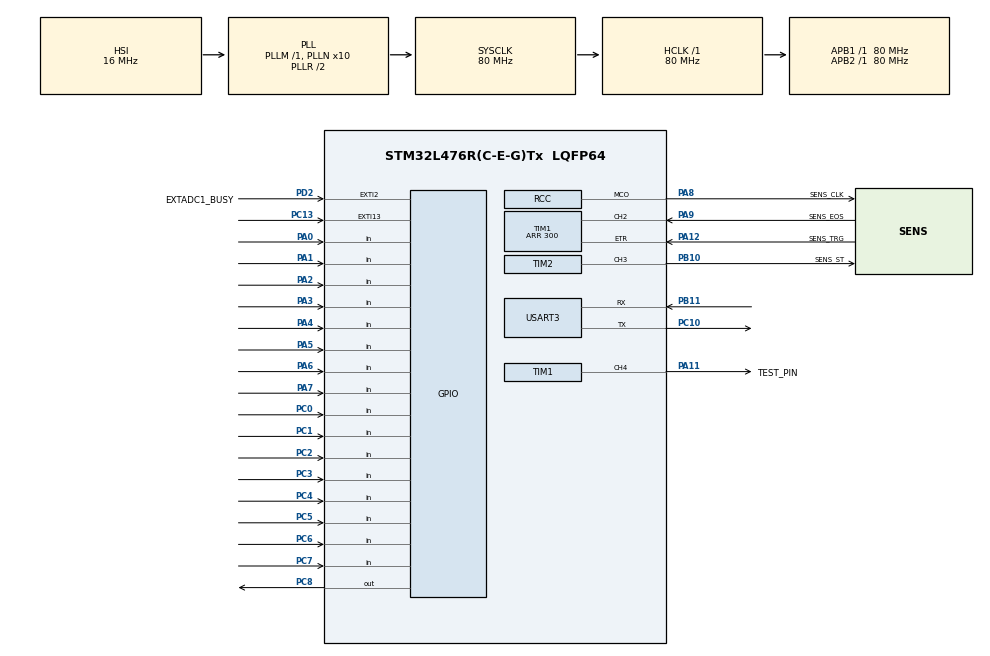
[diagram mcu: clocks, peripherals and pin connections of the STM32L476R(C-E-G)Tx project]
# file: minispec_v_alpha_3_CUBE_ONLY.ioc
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Dma.MEMTOMEM.0.Direction=DMA_MEMORY_TO_MEMORY
Dma.MEMTOMEM.0.Instance=DMA1_Channel1
Dma.MEMTOMEM.0.MemDataAlignment=DMA_MDATAALIGN_HALFWORD
Dma.MEMTOMEM.0.MemInc=DMA_MINC_ENABLE
Dma.MEMTOMEM.0.Mode=DMA_NORMAL
Dma.MEMTOMEM.0.PeriphDataAlignment=DMA_PDATAALIGN_HALFWORD
Dma.MEMTOMEM.0.PeriphInc=DMA_PINC_ENABLE
Dma.MEMTOMEM.0.Priority=DMA_PRIORITY_VERY_HIGH
Dma.MEMTOMEM.1.Direction=DMA_MEMORY_TO_MEMORY
Dma.MEMTOMEM.1.Instance=DMA2_Channel1
Dma.MEMTOMEM.1.MemDataAlignment=DMA_MDATAALIGN_HALFWORD
Dma.MEMTOMEM.1.MemInc=DMA_MINC_ENABLE
Dma.MEMTOMEM.1.Mode=DMA_NORMAL
Dma.MEMTOMEM.1.PeriphDataAlignment=DMA_PDATAALIGN_HALFWORD
Dma.MEMTOMEM.1.PeriphInc=DMA_PINC_ENABLE
Dma.MEMTOMEM.1.Priority=DMA_PRIORITY_VERY_HIGH
Dma.Request0=MEMTOMEM
Dma.Request1=MEMTOMEM
Mcu.Family=STM32L4
Mcu.Name=STM32L476R(C-E-G)Tx
Mcu.Package=LQFP64
NVIC.EXTI2_IRQn=true\:0\:0\:false\:true\:true\:1
NVIC.PriorityGroup=NVIC_PRIORITYGROUP_4
NVIC.TIM1_CC_IRQn=true\:0\:0\:false\:true\:true\:4
NVIC.TIM1_UP_TIM16_IRQn=true\:0\:0\:false\:true\:true\:3
NVIC.USART3_IRQn=true\:0\:0\:false\:true\:true\:2
PA0.Signal=GPIO_Input
PA1.Signal=GPIO_Input
PA11.GPIO_Label=TEST_PIN
PA11.GPIO_ModeDefaultPP=GPIO_MODE_AF_PP
PA11.GPIO_PuPd=GPIO_NOPULL
PA11.GPIO_Speed=GPIO_SPEED_FREQ_LOW
PA11.Signal=S_TIM1_CH4
PA12.GPIO_Label=SENS_TRG
PA12.GPIO_Mode=GPIO_MODE_AF_PP
PA12.GPIO_PuPd=GPIO_NOPULL
PA12.GPIO_Speed=GPIO_SPEED_FREQ_LOW
PA12.Signal=S_TIM1_ETR
PA13.Signal=SYS_JTMS-SWDIO
PA14.Signal=SYS_JTCK-SWCLK
PA2.Signal=GPIO_Input
PA3.Signal=GPIO_Input
PA4.Signal=GPIO_Input
PA5.Signal=GPIO_Input
PA6.Signal=GPIO_Input
PA7.Signal=GPIO_Input
PA8.GPIO_Label=SENS_CLK
PA8.GPIO_Mode=GPIO_MODE_AF_PP
PA8.GPIO_PuPd=GPIO_NOPULL
PA8.GPIO_Speed=GPIO_SPEED_FREQ_LOW
PA8.Mode=Clock-out
PA8.Signal=RCC_MCO
PA9.GPIO_Label=SENS_EOS
PA9.GPIO_ModeDefaultPP=GPIO_MODE_AF_PP
PA9.GPIO_PuPd=GPIO_NOPULL
PA9.GPIO_Speed=GPIO_SPEED_FREQ_LOW
PA9.Signal=S_TIM1_CH2
PB10.GPIO_Label=SENS_ST
PB10.GPIO_ModeDefaultPP=GPIO_MODE_AF_PP
PB10.GPIO_PuPd=GPIO_NOPULL
PB10.GPIO_Speed=GPIO_SPEED_FREQ_LOW
PB10.Signal=S_TIM2_CH3
PB11.Mode=Asynchronous
PB11.Signal=USART3_RX
PB3.Signal=SYS_JTDO-SWO
PC0.Signal=GPIO_Input
PC1.Signal=GPIO_Input
PC10.Mode=Asynchronous
PC10.Signal=USART3_TX
PC13.GPIO_ModeDefaultEXTI=GPIO_MODE_IT_RISING
PC13.GPIO_PuPd=GPIO_NOPULL
PC13.Signal=GPXTI13
PC14/OSC32_IN.Mode=LSE-External-Oscillator
PC14/OSC32_IN.Signal=RCC_OSC32_IN
PC15/OSC32_OUT.Mode=LSE-External-Oscillator
PC15/OSC32_OUT.Signal=RCC_OSC32_OUT
PC2.Signal=GPIO_Input
PC3.Signal=GPIO_Input
PC4.Signal=GPIO_Input
PC5.Signal=GPIO_Input
PC6.Signal=GPIO_Input
PC7.Signal=GPIO_Input
PC8.GPIO_ModeDefaultOutputPP=GPIO_MODE_OUTPUT_PP
PC8.GPIO_PuPd=GPIO_NOPULL
PC8.GPIO_Speed=GPIO_SPEED_FREQ_LOW
PC8.PinState=GPIO_PIN_RESET
PC8.Signal=GPIO_Output
PD2.GPIO_Label=EXTADC1_BUSY
PD2.GPIO_ModeDefaultEXTI=GPIO_MODE_IT_RISING
PD2.GPIO_PuPd=GPIO_NOPULL
PD2.Signal=GPXTI2
PH0/OSC_IN.Signal=RCC_OSC_IN
PH1/OSC_OUT.Signal=RCC_OSC_OUT
ProjectManager.HeapSize=0x2000
ProjectManager.StackSize=0x4000
ProjectManager.TargetToolchain=SW4STM32
RCC.ADCFreq_Value=64000000
RCC.AHBFreq_Value=80000000
RCC.APB1Freq_Value=80000000
RCC.APB1TimFreq_Value=80000000
RCC.APB2Freq_Value=80000000
RCC.APB2TimFreq_Value=80000000
RCC.CortexFreq_Value=80000000
RCC.HCLKFreq_Value=80000000
RCC.HSE_VALUE=8000000
RCC.HSI_VALUE=16000000
RCC.MSI_VALUE=4000000
RCC.PLLN=10
RCC.PLLSourceVirtual=RCC_PLLSOURCE_HSI
RCC.PREFETCH_ENABLE=1
RCC.RCC_MCO1Source=RCC_MCO1SOURCE_HSI
RCC.RCC_MCODiv=RCC_MCODIV_16
RCC.SYSCLKFreq_VALUE=80000000
RCC.SYSCLKSource=RCC_SYSCLKSOURCE_PLLCLK
RCC.USBFreq_Value=64000000
RCC.VCOOutputFreq_Value=160000000
RCC.VDD_VALUE=3.3
SH.S_TIM1_CH2.0=TIM1_CH2,Input_Capture2_from_TI2
SH.S_TIM1_CH4.0=TIM1_CH4,PWM Generation4 CH4
SH.S_TIM1_ETR.0=TIM1_ETR,ClockSourceETR_Mode2
SH.S_TIM2_CH3.0=TIM2_CH3,PWM Generation3 CH3
TIM1.Channel-Input_Capture2_from_TI2=TIM_CHANNEL_2
TIM1.Channel-PWM\ Generation4\ CH4=TIM_CHANNEL_4
TIM1.ClockPolarity=TIM_CLOCKPOLARITY_INVERTED
TIM1.OCMode_PWM-PWM\ Generation4\ CH4=TIM_OCMODE_PWM2
TIM1.OCPolarity_4=TIM_OCPOLARITY_HIGH
TIM1.Period=300
TIM1.Pulse-PWM\ Generation4\ CH4=80
TIM2.Channel-PWM\ Generation3\ CH3=TIM_CHANNEL_3
TIM2.OCMode_PWM-PWM\ Generation3\ CH3=TIM_OCMODE_PWM2
TIM2.OCPolarity_3=TIM_OCPOLARITY_HIGH
TIM2.Period=1100
TIM2.Prescaler=80
TIM2.Pulse-PWM\ Generation3\ CH3=1
TIM2.TIM_MasterOutputTrigger=TIM_TRGO_UPDATE
TIM2.TIM_MasterSlaveMode=TIM_MASTERSLAVEMODE_ENABLE
USART3.DMADisableonRxErrorParam=UART_ADVFEATURE_DMA_DISABLEONRXERROR
USART3.OverrunDisableParam=UART_ADVFEATURE_OVERRUN_DISABLE
USART3.VirtualMode-Asynchronous=VM_ASYNC
USART3.WordLength=WORDLENGTH_8B
VP_TIM1_VS_ClockSourceITR.Mode=TriggerSource_ITR1
VP_TIM1_VS_ControllerModeTrigger.Mode=Trigger Mode
VP_TIM1_VS_OPM.Mode=OPM_bit
VP_TIM2_VS_ClockSourceINT.Mode=Internal
VP_TIM2_VS_OPM.Mode=OPM_bit
VP_TIM5_VS_ClockSourceINT.Mode=Internal
board=NUCLEO-L476RG

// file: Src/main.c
/**
  ******************************************************************************
  * File Name          : main.c
  * Description        : Main program body
  ******************************************************************************
  *
  * COPYRIGHT(c) 2017 STMicroelectronics
  *
  * Redistribution and use in source and binary forms, with or without modification,
  * are permitted provided that the following conditions are met:
  *   1. Redistributions of source code must retain the above copyright notice,
  *      this list of conditions and the following disclaimer.
  *   2. Redistributions in binary form must reproduce the above copyright notice,
  *      this list of conditions and the following disclaimer in the documentation
  *      and/or other materials provided with the distribution.
  *   3. Neither the name of STMicroelectronics nor the names of its contributors
  *      may be used to endorse or promote products derived from this software
  *      without specific prior written permission.
  *
  * THIS SOFTWARE IS PROVIDED BY THE COPYRIGHT HOLDERS AND CONTRIBUTORS "AS IS"
  * AND ANY EXPRESS OR IMPLIED WARRANTIES, INCLUDING, BUT NOT LIMITED TO, THE
  * IMPLIED WARRANTIES OF MERCHANTABILITY AND FITNESS FOR A PARTICULAR PURPOSE ARE
  * DISCLAIMED. IN NO EVENT SHALL THE COPYRIGHT HOLDER OR CONTRIBUTORS BE LIABLE
  * FOR ANY DIRECT, INDIRECT, INCIDENTAL, SPECIAL, EXEMPLARY, OR CONSEQUENTIAL
  * DAMAGES (INCLUDING, BUT NOT LIMITED TO, PROCUREMENT OF SUBSTITUTE GOODS OR
  * SERVICES; LOSS OF USE, DATA, OR PROFITS; OR BUSINESS INTERRUPTION) HOWEVER
  * CAUSED AND ON ANY THEORY OF LIABILITY, WHETHER IN CONTRACT, STRICT LIABILITY,
  * OR TORT (INCLUDING NEGLIGENCE OR OTHERWISE) ARISING IN ANY WAY OUT OF THE USE
  * OF THIS SOFTWARE, EVEN IF ADVISED OF THE POSSIBILITY OF SUCH DAMAGE.
  *
  ******************************************************************************
  */
#include "main.h"
#include "stm32l4xx_hal.h"
#include "dma.h"
#include "tim.h"
#include "usart.h"
#include "gpio.h"

/* USER CODE BEGIN Includes */
#include "stdio.h"
#include "string.h"
/* USER CODE END Includes */

/* USER CODE BEGIN PV */
/* Private variables ---------------------------------------------------------*/

/* USER CODE END PV */

void SystemClock_Config(void);
void Error_Handler(void);
static void MX_NVIC_Init(void);

/* USER CODE BEGIN PFP */
/* Private function prototypes -----------------------------------------------*/

/* USER CODE END PFP */

/* USER CODE BEGIN 0 */
volatile uint8_t cmd_flag;
volatile uint16_t cmd_bytes;
/* USER CODE END 0 */

int main(void)
{

  /* MCU Configuration----------------------------------------------------------*/

  /* Reset of all peripherals, Initializes the Flash interface and the Systick. */
  HAL_Init();

  /* Configure the system clock */
  SystemClock_Config();

  /* Initialize all configured peripherals */
  MX_GPIO_Init();
  MX_DMA_Init();
  MX_TIM2_Init();
  MX_TIM1_Init();
  MX_TIM5_Init();
  MX_USART3_UART_Init();

  /* Initialize interrupts */
  MX_NVIC_Init();

  /* USER CODE BEGIN 2 */

	//timer

	// ST
	TIM2->CCER |= TIM_CCER_CC3E;

	// TEST
	TIM1->CCER |= TIM_CCER_CC4E;
	__HAL_TIM_MOE_ENABLE( &htim1 );

	//start tim2 (ST)
	__HAL_TIM_ENABLE( &htim2 );

//	//modbus activation
//	uint32_t cr1 = 0;
//	char c;
//	//save cr1 status + reset RE and UE bit for modifying ADD[7:0]
//	cr1 = USART3->CR1;
//	USART3->CR1 &= ~(USART_CR1_RE | USART_CR1_UE);
//
//	c = '\r';
//	USART3->CR2 = (USART_CR2_ADD_Msk & (c << USART_CR2_ADD_Pos));
//
//	// restore RE and UE bit
//	USART3->CR1 = cr1;
//	//enable char match IR
//	USART3->CR1 |= USART_CR1_CMIE;
//
//	static uint8_t recv_buf[51];
//	memset( recv_buf, 0, 50 );
//	recv_buf[50] = '\0';
//
//	static uint8_t send_buf[51];
//	memset( send_buf, 'a', 50 );
//	send_buf[50] = '\0';
//	HAL_UART_Receive_IT( &huart3, recv_buf, 50 );
  /* USER CODE END 2 */

  /* Infinite loop */
	while( 1 )
	{

  /* USER CODE BEGIN 3 */

		/* TIMER TEST */
//		TIM_CCxChannelCmd((&htim2)->Instance, TIM_CHANNEL_3, TIM_CCx_ENABLE);
//		HAL_TIM_OC_Start(&htim1, TIM_CHANNEL_2); // HACK as PWM_START do not start
// TIM2 CH3 high @ first rising edge (first full pulse) -->> pulse 1
// low @ 10th rising edge (9 full pulses before) -->> period 9
// with low also update event (ARR overflow)
//		HAL_Delay( 50 );
		/* UART TEST*/

//		if( cmd_flag != 0 )
//		{
//			cmd_flag = 0;
//
//			if( memchr( (const void *) recv_buf, 'S', cmd_bytes ) != NULL )
//			{
//
////				HAL_UART_Transmit( &huart3, (uint8_t *) "\n", 1, 100 );
//				HAL_UART_Transmit( &huart3, (uint8_t *) send_buf, sizeof(send_buf), 8000000 );
////				HAL_UART_Transmit( &huart3, (uint8_t *) "\n", 1, 100 );
//				HAL_Delay( 50 );
//			}
//			memset( recv_buf, 0, cmd_bytes );
//			cmd_bytes = 0;
//			HAL_UART_Receive_IT( &huart3, recv_buf, 50 );
//		}
	}
  /* USER CODE END 3 */

}

/** System Clock Configuration
*/
void SystemClock_Config(void)
{

  RCC_OscInitTypeDef RCC_OscInitStruct;
  RCC_ClkInitTypeDef RCC_ClkInitStruct;
  RCC_PeriphCLKInitTypeDef PeriphClkInit;

    /**Initializes the CPU, AHB and APB busses clocks
    */
  RCC_OscInitStruct.OscillatorType = RCC_OSCILLATORTYPE_HSI;
  RCC_OscInitStruct.HSIState = RCC_HSI_ON;
  RCC_OscInitStruct.HSICalibrationValue = 16;
  RCC_OscInitStruct.PLL.PLLState = RCC_PLL_ON;
  RCC_OscInitStruct.PLL.PLLSource = RCC_PLLSOURCE_HSI;
  RCC_OscInitStruct.PLL.PLLM = 1;
  RCC_OscInitStruct.PLL.PLLN = 10;
  RCC_OscInitStruct.PLL.PLLP = RCC_PLLP_DIV7;
  RCC_OscInitStruct.PLL.PLLQ = RCC_PLLQ_DIV2;
  RCC_OscInitStruct.PLL.PLLR = RCC_PLLR_DIV2;
  if (HAL_RCC_OscConfig(&RCC_OscInitStruct) != HAL_OK)
  {
    Error_Handler();
  }

    /**Initializes the CPU, AHB and APB busses clocks
    */
  RCC_ClkInitStruct.ClockType = RCC_CLOCKTYPE_HCLK|RCC_CLOCKTYPE_SYSCLK
                              |RCC_CLOCKTYPE_PCLK1|RCC_CLOCKTYPE_PCLK2;
  RCC_ClkInitStruct.SYSCLKSource = RCC_SYSCLKSOURCE_PLLCLK;
  RCC_ClkInitStruct.AHBCLKDivider = RCC_SYSCLK_DIV1;
  RCC_ClkInitStruct.APB1CLKDivider = RCC_HCLK_DIV1;
  RCC_ClkInitStruct.APB2CLKDivider = RCC_HCLK_DIV1;

  if (HAL_RCC_ClockConfig(&RCC_ClkInitStruct, FLASH_LATENCY_4) != HAL_OK)
  {
    Error_Handler();
  }

  PeriphClkInit.PeriphClockSelection = RCC_PERIPHCLK_USART3;
  PeriphClkInit.Usart3ClockSelection = RCC_USART3CLKSOURCE_PCLK1;
  if (HAL_RCCEx_PeriphCLKConfig(&PeriphClkInit) != HAL_OK)
  {
    Error_Handler();
  }

  HAL_RCC_MCOConfig(RCC_MCO1, RCC_MCO1SOURCE_HSI, RCC_MCODIV_16);

    /**Configure the main internal regulator output voltage
    */
  if (HAL_PWREx_ControlVoltageScaling(PWR_REGULATOR_VOLTAGE_SCALE1) != HAL_OK)
  {
    Error_Handler();
  }

    /**Configure the Systick interrupt time
    */
  HAL_SYSTICK_Config(HAL_RCC_GetHCLKFreq()/1000);

    /**Configure the Systick
    */
  HAL_SYSTICK_CLKSourceConfig(SYSTICK_CLKSOURCE_HCLK);

  /* SysTick_IRQn interrupt configuration */
  HAL_NVIC_SetPriority(SysTick_IRQn, 0, 0);
}

/** NVIC Configuration
*/
static void MX_NVIC_Init(void)
{
  /* EXTI2_IRQn interrupt configuration */
  HAL_NVIC_SetPriority(EXTI2_IRQn, 0, 0);
  HAL_NVIC_EnableIRQ(EXTI2_IRQn);
  /* USART3_IRQn interrupt configuration */
  HAL_NVIC_SetPriority(USART3_IRQn, 0, 0);
  HAL_NVIC_EnableIRQ(USART3_IRQn);
  /* TIM1_UP_TIM16_IRQn interrupt configuration */
  HAL_NVIC_SetPriority(TIM1_UP_TIM16_IRQn, 0, 0);
  HAL_NVIC_EnableIRQ(TIM1_UP_TIM16_IRQn);
  /* TIM1_CC_IRQn interrupt configuration */
  HAL_NVIC_SetPriority(TIM1_CC_IRQn, 0, 0);
  HAL_NVIC_EnableIRQ(TIM1_CC_IRQn);
}

void Error_Handler(void)
{
	while( 1 )
	{
	}
}

/************************ (C) COPYRIGHT STMicroelectronics *****END OF FILE****/
